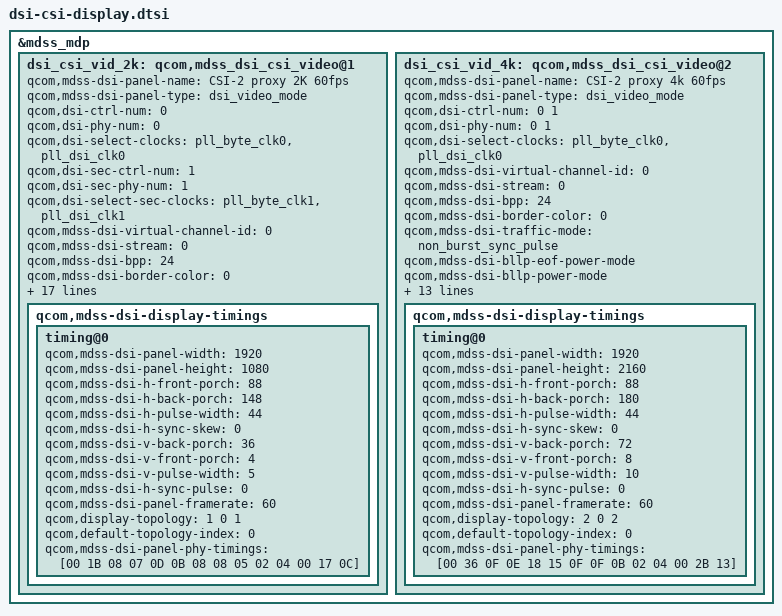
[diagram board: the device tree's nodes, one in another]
&mdss_mdp {
	dsi_csi_vid_2k: qcom,mdss_dsi_csi_video@1 {
		qcom,mdss-dsi-panel-name = "CSI-2 proxy 2K 60fps";
		qcom,mdss-dsi-panel-type = "dsi_video_mode";

		qcom,dsi-ctrl-num = <0>;
		qcom,dsi-phy-num = <0>;
		qcom,dsi-select-clocks = "pll_byte_clk0", "pll_dsi_clk0";

		qcom,dsi-sec-ctrl-num = <1>;
		qcom,dsi-sec-phy-num = <1>;
		qcom,dsi-select-sec-clocks = "pll_byte_clk1", "pll_dsi_clk1";

		qcom,mdss-dsi-virtual-channel-id = <0>;
		qcom,mdss-dsi-stream = <0>;
		qcom,mdss-dsi-bpp = <24>;
		qcom,mdss-dsi-border-color = <0>;
		qcom,mdss-dsi-traffic-mode = "non_burst_sync_pulse";
		qcom,mdss-dsi-bllp-eof-power-mode;
		qcom,mdss-dsi-bllp-power-mode;
		/delete-property/ qcom,mdss-dsi-hsa-power-mode;
		qcom,mdss-dsi-hbp-power-mode;
		/delete-property/ qcom,mdss-dsi-hfp-power-mode;

		qcom,mdss-dsi-lane-0-state;
		qcom,mdss-dsi-lane-1-state;
		qcom,mdss-dsi-lane-2-state;
		qcom,mdss-dsi-lane-3-state;
		qcom,mdss-dsi-dma-trigger = "trigger_sw";
		qcom,mdss-dsi-mdp-trigger = "none";
		qcom,mdss-dsi-t-clk-post = <0x13>;
		qcom,mdss-dsi-t-clk-pre = <0x29>;
		qcom,mdss-dsi-force-clock-lane-hs;
		qcom,mdss-dsi-ext-bridge-mode;

		qcom,csi-proxy-enable;
		qcom,mdss-dsi-color-order = "rgb_swap_rgb";

		qcom,mdss-dsi-display-timings {
			timing@0{
				qcom,mdss-dsi-panel-width = <1920>;
				qcom,mdss-dsi-panel-height = <1080>;
				qcom,mdss-dsi-h-front-porch = <88>;
				qcom,mdss-dsi-h-back-porch = <148>;
				qcom,mdss-dsi-h-pulse-width = <44>;
				qcom,mdss-dsi-h-sync-skew = <0>;
				qcom,mdss-dsi-v-back-porch = <36>;
				qcom,mdss-dsi-v-front-porch = <4>;
				qcom,mdss-dsi-v-pulse-width = <5>;
				qcom,mdss-dsi-h-sync-pulse = <0>;
				qcom,mdss-dsi-panel-framerate = <60>;
				qcom,display-topology = <1 0 1>;
				qcom,default-topology-index = <0>;
				qcom,mdss-dsi-panel-phy-timings = [00 1B
						08 07 0D 0B 08 08 05 02 04 00 17 0C];
			};
		};
	};

	dsi_csi_vid_4k: qcom,mdss_dsi_csi_video@2 {
		qcom,mdss-dsi-panel-name = "CSI-2 proxy 4k 60fps";
		qcom,mdss-dsi-panel-type = "dsi_video_mode";

		qcom,dsi-ctrl-num = <0 1>;
		qcom,dsi-phy-num = <0 1>;
		qcom,dsi-select-clocks = "pll_byte_clk0", "pll_dsi_clk0";

		qcom,mdss-dsi-virtual-channel-id = <0>;
		qcom,mdss-dsi-stream = <0>;
		qcom,mdss-dsi-bpp = <24>;
		qcom,mdss-dsi-border-color = <0>;
		qcom,mdss-dsi-traffic-mode = "non_burst_sync_pulse";
		qcom,mdss-dsi-bllp-eof-power-mode;
		qcom,mdss-dsi-bllp-power-mode;
		/delete-property/ qcom,mdss-dsi-hsa-power-mode;
		qcom,mdss-dsi-hbp-power-mode;
		/delete-property/ qcom,mdss-dsi-hfp-power-mode;

		qcom,mdss-dsi-lane-0-state;
		qcom,mdss-dsi-lane-1-state;
		qcom,mdss-dsi-lane-2-state;
		qcom,mdss-dsi-lane-3-state;
		qcom,mdss-dsi-dma-trigger = "trigger_sw";
		qcom,mdss-dsi-mdp-trigger = "none";
		qcom,mdss-dsi-t-clk-post = <0x13>;
		qcom,mdss-dsi-t-clk-pre = <0x29>;
		qcom,mdss-dsi-force-clock-lane-hs;
		qcom,mdss-dsi-ext-bridge-mode;

		qcom,csi-proxy-enable;
		qcom,mdss-dsi-color-order = "rgb_swap_rgb";

		qcom,mdss-dsi-display-timings {
			timing@0{
				qcom,mdss-dsi-panel-width = <1920>;
				qcom,mdss-dsi-panel-height = <2160>;
				qcom,mdss-dsi-h-front-porch = <88>;
				qcom,mdss-dsi-h-back-porch = <180>;
				qcom,mdss-dsi-h-pulse-width = <44>;
				qcom,mdss-dsi-h-sync-skew = <0>;
				qcom,mdss-dsi-v-back-porch = <72>;
				qcom,mdss-dsi-v-front-porch = <8>;
				qcom,mdss-dsi-v-pulse-width = <10>;
				qcom,mdss-dsi-h-sync-pulse = <0>;
				qcom,mdss-dsi-panel-framerate = <60>;
				qcom,display-topology = <2 0 2>;
				qcom,default-topology-index = <0>;
				qcom,mdss-dsi-panel-phy-timings = [00 36
						0F 0E 18 15 0F 0F 0B 02 04 00 2B 13];
			};
		};
	};
};
